AUTOSAR XML (schema 4-2-2)
package /ComponentTypes
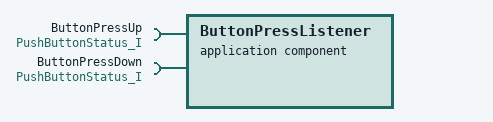
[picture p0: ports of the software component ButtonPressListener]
  application sw component type ButtonPressListener
    require port ButtonPressUp: queued-receiver-com-spec{data-element=PushButtonStatus, queue-length=10}, required-interface=PushButtonStatus_I
    require port ButtonPressDown: queued-receiver-com-spec{data-element=PushButtonStatus, queue-length=10}, required-interface=PushButtonStatus_I
    behavior ButtonPressListener_InternalBehavior
      port-api-options:
        enable-take-address=false, indirect-api=false, port=ButtonPressDown
        enable-take-address=false, indirect-api=false, port=ButtonPressUp
  swc implementation ButtonPressListener_Implementation: behavior=ButtonPressListener_InternalBehavior
    code-descriptors:
      code Default: artifact-descriptors=autosar-engineering-object={short-label=Default, category=SWSRC}
